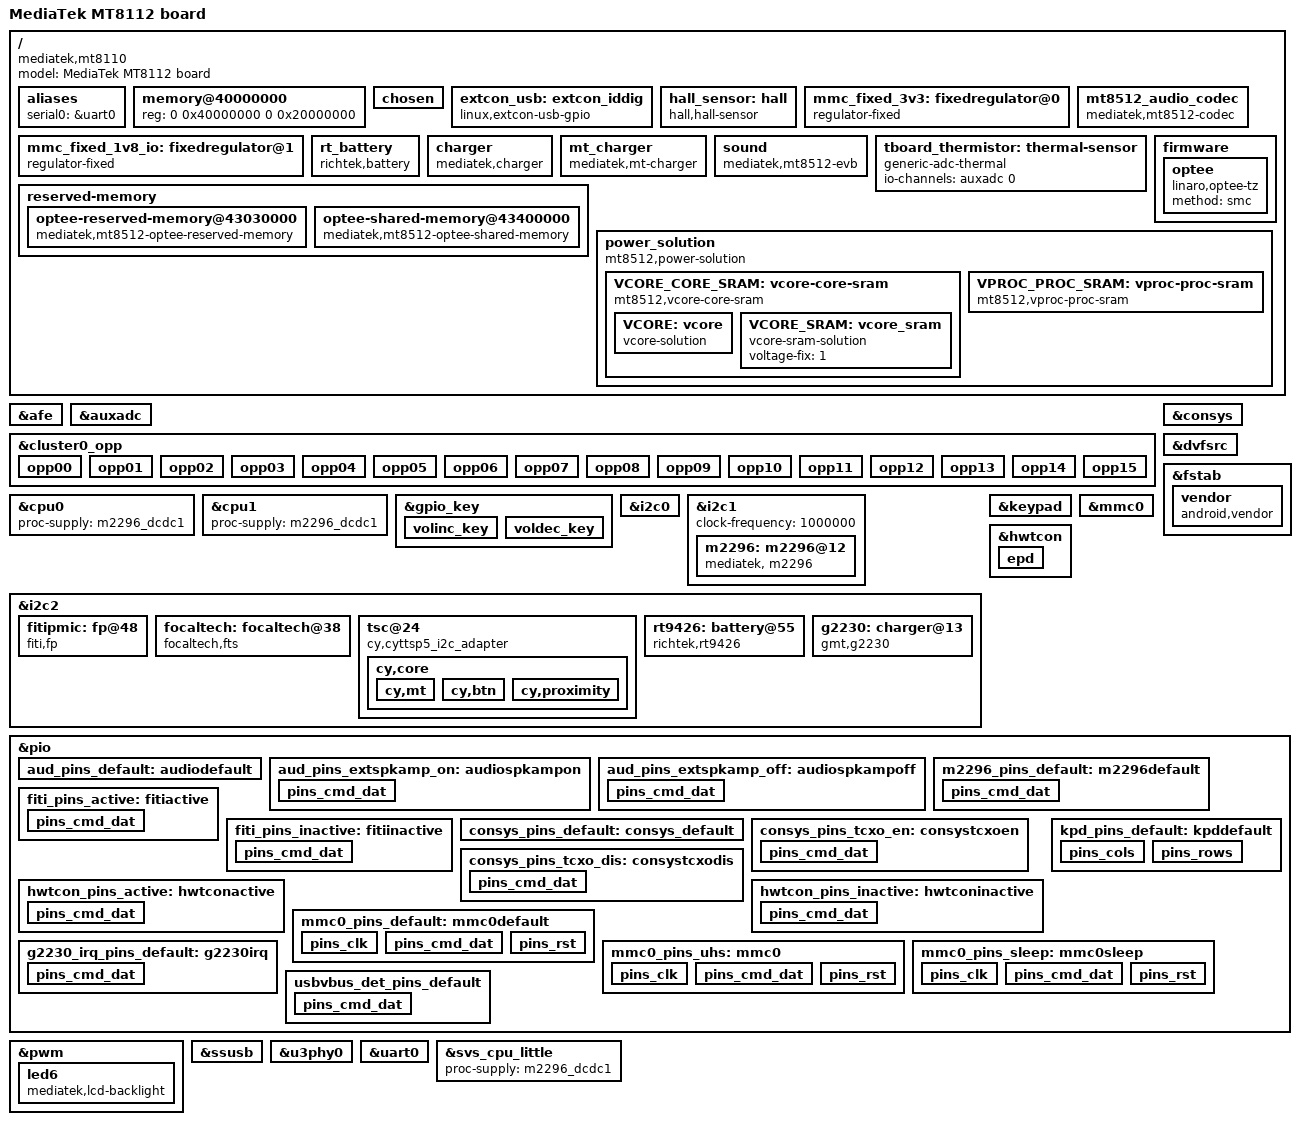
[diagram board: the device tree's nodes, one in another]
/*
 * Copyright (c) 2019 MediaTek Inc.
 *
 * SPDX-License-Identifier: (GPL-2.0 OR MIT)
 */

/dts-v1/;
#include "mt8112.dtsi"

/ {
	model = "MediaTek MT8112 board";
	compatible = "mediatek,mt8110", "mediatek,mt8512";

	aliases {
		serial0 = &uart0;
	};

	memory@40000000 {
		device_type = "memory";
		reg = <0 0x40000000 0 0x20000000>;
	};
	chosen {
		bootargs = "console=ttyS0,921600n1 \
		root=PARTUUID=936e1662-2b63-435d-859d-1b9e5a838335 \
		rootwait skip_initramfs \
		earlycon=uart8250,mmio32,0x11002000 \
		initcall_debug androidboot.hardware=mt8512 \
		firmware_class.path=/vendor/firmware";
	};
	extcon_usb: extcon_iddig {
		compatible = "linux,extcon-usb-gpio";
		vbus-gpios = <&pio 35 0>;
		pinctrl-names = "default";
		pinctrl-0 = <&usbvbus_det_pins_default>;
	};

	hall_sensor: hall {
		compatible = "hall,hall-sensor";
		interrupt-parent = <&pio>;
		interrupts = <30 IRQ_TYPE_LEVEL_LOW>;
		int-gpio = <&pio 30 0>;
		sensor-name = "hall_sensor_1";
		sensor-num = <1>;
	};

	mmc_fixed_3v3: fixedregulator@0 {
		compatible = "regulator-fixed";
		regulator-name = "mmc_power";
		regulator-min-microvolt = <3300000>;
		regulator-max-microvolt = <3300000>;
		enable-active-high;
		regulator-always-on;
	};

	mmc_fixed_1v8_io: fixedregulator@1 {
		compatible = "regulator-fixed";
		regulator-name = "mmc_io";
		regulator-min-microvolt = <1800000>;
		regulator-max-microvolt = <1800000>;
		enable-active-high;
		regulator-always-on;
	};

	mt8512_audio_codec: mt8512_audio_codec {
		compatible = "mediatek,mt8512-codec";
		mediatek,afe-regmap = <&afe>;
		mediatek,apmixedsys-regmap = <&apmixedsys>;
		mediatek,downlink-nle-support = <1>;
		clocks = <&topckgen CLK_TOP_AUD_INTBUS_SEL>;
		clock-names = "bus";
		io-channels = <&auxadc 5>;
		io-channel-names = "adc-ch5";
	};

	rt_battery: rt_battery {
		compatible = "richtek,battery";
		status = "okay";
	};

	charger: charger {
		compatible = "mediatek,charger";
		algorithm_name = "switch_charging";
		/* enable_sw_jeita; */

		/* common */
		battery_cv = <4350000>;
		max_charger_voltage = <6500000>;
		max_charging_time = <72000>; /* 20 * 60 * 60 secs */
		enable_sw_safety_timer;

		/* charging current */
		usb_charger_current_suspend = <0>;
		usb_charger_current_unconfigured = <70000>;
		usb_charger_current_configured = <400000>;
		usb_charger_current = <400000>;
		ac_charger_current = <1000000>;
		ac_charger_input_current = <3000000>;
		non_std_ac_charger_current = <2000000>;
		charging_host_charger_current = <400000>;
		apple_1_0a_charger_current = <650000>;
		apple_2_1a_charger_current = <800000>;
		ta_ac_charger_current = <1000000>;

		/* sw jeita */
		jeita_temp_above_t4_cv_voltage = <4240000>;
		jeita_temp_t3_to_t4_cv_voltage = <4240000>;
		jeita_temp_t2_to_t3_cv_voltage = <4340000>;
		jeita_temp_t1_to_t2_cv_voltage = <4240000>;
		jeita_temp_t0_to_t1_cv_voltage = <4040000>;
		jeita_temp_below_t0_cv_voltage = <4040000>;
		temp_t4_threshold = <50>;
		temp_t4_thres_minus_x_degree = <47>;
		temp_t3_threshold = <45>;
		temp_t3_thres_minus_x_degree = <39>;
		temp_t2_threshold = <10>;
		temp_t2_thres_plus_x_degree = <16>;
		temp_t1_threshold = <0>;
		temp_t1_thres_plus_x_degree = <6>;
		temp_t0_threshold = <0>;
		temp_t0_thres_plus_x_degree = <0>;
		temp_neg_10_threshold = <0>;

		/* battery temperature protection */
		enable_min_charge_temperature;
		min_charge_temperature = <0>;
		min_charge_temperature_plus_x_degree = <6>;
		max_charge_temperature = <50>;
		max_charge_temperature_minus_x_degree = <47>;
	};

	mt_charger: mt_charger {
		compatible = "mediatek,mt-charger";
		status = "okay";
	};

	reserved-memory {
		optee-reserved-memory@43030000 {
			compatible = "mediatek,mt8512-optee-reserved-memory";
			no-map;
			reg = <0 0x43030000 0 0x3d0000>;
		};
		optee-shared-memory@43400000 {
			compatible = "mediatek,mt8512-optee-shared-memory";
			no-map;
			reg = <0 0x43400000 0 0x100000>;
		};
	};

	sound: sound {
		compatible = "mediatek,mt8512-evb";
		mediatek,platform = <&afe>;
		mediatek,int-adda-audio-codec=<&mt8512_audio_codec>;
		mediatek,int-adda-codec-dai-name="mt8512-codec-dai";
		pinctrl-names = "default",
			"ext_spk_amp_on",
			"ext_spk_amp_off";
		pinctrl-0 = <&aud_pins_default>;
		pinctrl-1 = <&aud_pins_extspkamp_on>;
		pinctrl-2 = <&aud_pins_extspkamp_off>;
		status = "okay";
	};

	tboard_thermistor: thermal-sensor {
		compatible = "generic-adc-thermal";
		#thermal-sensor-cells = <0>;
		io-channels = <&auxadc 0>;
		io-channel-names = "sensor-channel";
	};

	firmware {
		optee {
			compatible = "linaro,optee-tz";
			method = "smc";
		};
	};

	power_solution: power_solution {
		compatible = "mt8512,power-solution";
		power-states = <&VCORE_CORE_SRAM &VPROC_PROC_SRAM>;
		device-names = <0>;
		clk-on = <0>;
		buck-name = "rt";

		VCORE_CORE_SRAM: vcore-core-sram {
			compatible = "mt8512,vcore-core-sram";
			merge = <0>;
			bucks = <&VCORE &VCORE_SRAM>;

			VCORE: vcore {
				compatible = "vcore-solution";
				type = "gpio";
				channel = <1>;
				latency = <100>;
				voltage-fix = <0>;
			};

			VCORE_SRAM: vcore_sram {
				compatible = "vcore-sram-solution";
				voltage-fix = <1>;
			};
		};

		VPROC_PROC_SRAM: vproc-proc-sram {
			compatible = "mt8512,vproc-proc-sram";
			merge = <1>;
			fix = <1>;
		};
	};
};

&afe {
	status = "okay";
};

&auxadc {
	status = "okay";
};

&cluster0_opp {
	opp00 {
		opp-hz = /bits/ 64 <600000000>;
		opp-microvolt = <800000>;
	};
	opp01 {
		opp-hz = /bits/ 64 <666000000>;
		opp-microvolt = <800000>;
	};
	opp02 {
		opp-hz = /bits/ 64 <733000000>;
		opp-microvolt = <800000>;
	};
	opp03 {
		opp-hz = /bits/ 64 <833000000>;
		opp-microvolt = <800000>;
	};
	opp04 {
		opp-hz = /bits/ 64 <1000000000>;
		opp-microvolt = <800000>;
	};
	opp05 {
		opp-hz = /bits/ 64 <1133000000>;
		opp-microvolt = <800000>;
	};
	opp06 {
		opp-hz = /bits/ 64 <1266000000>;
		opp-microvolt = <800000>;
	};
	opp07 {
		opp-hz = /bits/ 64 <1400000000>;
		opp-microvolt = <800000>;
	};
	opp08 {
		opp-hz = /bits/ 64 <1467000000>;
		opp-microvolt = <825000>;
	};
	opp09 {
		opp-hz = /bits/ 64 <1534000000>;
		opp-microvolt = <850000>;
	};
	opp10 {
		opp-hz = /bits/ 64 <1588000000>;
		opp-microvolt = <868750>;
	};
	opp11 {
		opp-hz = /bits/ 64 <1702000000>;
		opp-microvolt = <912500>;
	};
	opp12 {
		opp-hz = /bits/ 64 <1786000000>;
		opp-microvolt = <943750>;
	};
	opp13 {
		opp-hz = /bits/ 64 <1870000000>;
		opp-microvolt = <975000>;
	};
	opp14 {
		opp-hz = /bits/ 64 <1938000000>;
		opp-microvolt = <1000000>;
	};
	opp15 {
		opp-hz = /bits/ 64 <2000000000>;
		opp-microvolt = <1025000>;
	};
};

&cpu0 {
	proc-supply = <&m2296_dcdc1>;
};

&cpu1 {
	proc-supply = <&m2296_dcdc1>;
};

&consys {
	pinctrl-names = "default",
		"consys_pins_tcxo_en",
		"consys_pins_tcxo_dis";
	pinctrl-0 = <&consys_pins_default>;
	pinctrl-1 = <&consys_pins_tcxo_en>;
	pinctrl-2 = <&consys_pins_tcxo_dis>;
	1v8_en = <&pio 57 0>;	/* 1.8V */
	3v3_en = <&pio 56 0>;	/* 3.3V */
	status = "okay";
};

&dvfsrc {
	status = "okay";
	dvfsrc-pwr-index = <7>;
	clocks = <&infrasys CLK_INFRA_DVFSRC>,
		<&topckgen CLK_TOP_I2C_SEL>,
		<&infrasys CLK_INFRA_I2C0_AXI>;
	clock-names = "dvfsrc",
		"i2c_sel",
		"i2c0";
};

&fstab {
	vendor {
		compatible = "android,vendor";
		dev = "/dev/block/platform/11230000.mmc/by-name/vendor";
		type = "ext4";
		mnt_flags = "ro";
		fsmgr_flags = "wait";
	};
};

&gpio_key {
	volinc_key{
		debounce-interval = <100>;
		gpios = <&pio 42 1>;
		linux,code = <115>;
		linux,input-type = <1>;
	};
	voldec_key{
		debounce-interval = <100>;
		gpios = <&pio 43 1>;
		linux,code = <114>;
		linux,input-type = <1>;
	};
};

&i2c0 {
	status = "okay";
};

&i2c1 {
	clock-frequency = <1000000>;
	status = "okay";

	m2296: m2296@12 {
		compatible = "mediatek, m2296";
		reg = <0x12>;
		interrupt-parent = <&pio>;
		interrupts = <62 IRQ_TYPE_EDGE_FALLING>;
		interrupt-controller;
		#interrupt-cells = <2>;
		pinctrl-names = "default";
		pinctrl-0 = <&m2296_pins_default>;
		system-power-controller;
		mediatek,pwrkey-code = <116>;
		status = "okay";
	};
};

&i2c2 {
	status = "okay";

	fitipmic: fp@48 {
		compatible = "fiti,fp";
		reg = <0x18>;
		vgh_ext = <0>;
		vgl_ext = <2000>;
		xon_len = <2510>;
		xon_delay = <40>;
		vgh = <25000>;
		vgl = <20000>;
		vcom_setting = <2770>;
		vghnm_setting = <3300>;
		vghnm_ext = <1500>;
		vpos = <15000>;
		vneg = <15000>;
		epd-pmic-en = <&pio 38 0>;
		epd-pmic-op = <&pio 9 0>;
		epd-pmic-nm = <&pio 10 0>;
		interrupt-parent = <&pio>;
		interrupts = <10 IRQ_TYPE_LEVEL_HIGH>;
		deb-gpios = <&pio 5 0>;
		debounce = <16>;
		/*epd-supply = <&m2296_dcdc3>;*/
		pinctrl-names = "active", "inactive";
		pinctrl-0 = <&fiti_pins_active>;
		pinctrl-1 = <&fiti_pins_inactive>;
		status = "okay";
	};

	focaltech:focaltech@38 {
		compatible = "focaltech,fts";
		reg = <0x38>;
		focaltech,name = "focaltech";
		focaltech,panel-coords = <0 0 0x400 0x2f6>;
		focaltech,display-coords = <0 0 0x400 0x2f6>;
		/*focaltech,i2c-pull-up;*/
		/*focaltech,no-force-update;*/
		focaltech,reset-gpio = <&pio 0 0>;
		focaltech,irq-gpio = <&pio 1 0>;
		/*wacom,pdctb = <&pio 4 0>;*/
		/*interrupt-parent = <&sysirq>;*/
		interrupt-parent = <&pio>;
		interrupts = <0 IRQ_TYPE_EDGE_FALLING>;
		focaltech,fw-name = "FT_Upgrade_App.i";
		focaltech,group-id = <0x01>;
		focaltech,hard-reset-delay-ms = <0x14>;
		focaltech,soft-reset-delay-ms = <0x0a>;
		focaltech,num-max-touches = <0x0a>;
		focaltech,fw-delay-aa-ms = <0x32>;
		focaltech,fw-delay-55-ms = <0x1e>;
		focaltech,fw-upgrade-id1 = <0x79>;
		focaltech,fw-upgrade-id2 = <0x03>;
		focaltech,fw-delay-readid-ms = <0x0a>;
		focaltech,fw-delay-era-flsh-ms = <0x7d0>;
		/*focaltech,fw-auto-cal;*/
		/*focaltech,fw-vkey-support;*/
		/*focaltech,ignore-id-check;*/
		/*focaltech,psensor-support;*/
		focaltech,power-regulator-support;
		focaltech,family-id = <0x54>;
		/*focaltech,button-map*/
		status = "okay";
	};

	tsc@24 {
		compatible = "cy,cyttsp5_i2c_adapter";
		reg = <0x24>;

		/* GPIO 1, high-to-low edge triggered */
		interrupts = <1 2>;
		interrupt-parent = <&pio>;
		cy,adapter_id = "cyttsp5_i2c_adapter";

		cy,core {
			cy,name = "cyttsp5_core";

			cy,irq_gpio = <&pio 1 0>;
			cy,rst_gpio = <&pio 0 0>;
			cy,hid_desc_register = <1>;
			/*CY_CORE_FLAG_RESTORE_PARAMETERS */
			cy,flags = <4>;
			/* CY_CORE_EWG_NONE */
			cy,easy_wakeup_gesture = <0>;
			cy,btn_keys = <172 /* KEY_HOMEPAGE */
	/* previously was KEY_HOME, new Android versions use KEY_HOMEPAGE */
				       139 /* KEY_MENU */
				       158 /* KEY_BACK */
				       217 /* KEY_SEARCH */
				       114 /* KEY_VOLUMEDOWN */
				       115 /* KEY_VOLUMEUP */
				       212 /* KEY_CAMERA */
				       116>; /* KEY_POWER */
			cy,btn_keys-tag = <0>;

			cy,mt {
				cy,name = "cyttsp5_mt";

				cy,inp_dev_name = "cyttsp5_mt";
	/* CY_MT_FLAG_FLIP | CY_MT_FLAG_INV_X | CY_MT_FLAG_INV_Y */
				cy,flags = <0x18>;
				cy,abs =
	/* ABS_MT_POSITION_X, CY_ABS_MIN_X, CY_ABS_MAX_X, 0, 0 */
					<0x35 0 880 0 0
	/* ABS_MT_POSITION_Y, CY_ABS_MIN_Y, CY_ABS_MAX_Y, 0, 0 */
					0x36 0 1280 0 0
	/* ABS_MT_PRESSURE, CY_ABS_MIN_P, CY_ABS_MAX_P, 0, 0 */
					0x3a 0 255 0 0
	/* CY_IGNORE_VALUE, CY_ABS_MIN_W, CY_ABS_MAX_W, 0, 0 */
					0xffff 0 255 0 0
	/* ABS_MT_TRACKING_ID, CY_ABS_MIN_T, CY_ABS_MAX_T, 0, 0 */
					0x39 0 15 0 0
	/* ABS_MT_TOUCH_MAJOR, 0, 255, 0, 0 */
					0x30 0 255 0 0
	/* ABS_MT_TOUCH_MINOR, 0, 255, 0, 0 */
					0x31 0 255 0 0
	/* ABS_MT_ORIENTATION, -127, 127, 0, 0 */
					0x34 0xffffff81 127 0 0
	/* ABS_MT_TOOL_TYPE, 0, MT_TOOL_MAX, 0, 0 */
					0x37 0 1 0 0
	/* ABS_MT_DISTANCE, 0, 255, 0, 0 */
					0x3b 0 255 0 0>;

				cy,vkeys_x = <720>;
				cy,vkeys_y = <1280>;

				cy,virtual_keys =
				/* KeyCode CenterX CenterY Width Height */
					/* KEY_BACK */
					<158 1360 90 160 180
					/* KEY_MENU */
					139 1360 270 160 180
					/* KEY_HOMEPAGE */
					172 1360 450 160 180
					/* KEY SEARCH */
					217 1360 630 160 180>;
			};

			cy,btn {
				cy,name = "cyttsp5_btn";

				cy,inp_dev_name = "cyttsp5_btn";
			};

			cy,proximity {
				cy,name = "cyttsp5_proximity";

				cy,inp_dev_name = "cyttsp5_proximity";
				cy,abs =
					<0x19 0 1 0 0>;
			};
		};
	};

	rt9426: battery@55 {
		compatible = "richtek,rt9426";
		reg = <0x55>;
		interrupt-parent = <&pio>;
		interrupts = <28 0>;
		status = "okay";
	};

	g2230:charger@13 {
		compatible = "gmt,g2230";
		charger_name = "primary_chg";
		pinctrl-names = "default";
		pinctrl-0 = <&g2230_irq_pins_default>;
		reg = <0x13>;
		chg_ce = <&pio 31 0>;
		chg_int = <&pio 29 0>;
		status = "okay";
	};
};

&keypad {
	pinctrl-names = "default";
	pinctrl-0 = <&kpd_pins_default>;
	status = "okay";
	mediatek,kpd-key-debounce = <1024>;
	mediatek,kpd-sw-pwrkey = <116>;
	mediatek,kpd-hw-pwrkey = <1>;
	mediatek,kpd-sw-rstkey  = <114>;
	mediatek,kpd-hw-rstkey = <3>;
	mediatek,kpd-use-extend-type = <0>;
	/*HW Keycode [0~3] -> Linux Keycode*/
	mediatek,kpd-hw-map-num = <72>;
	mediatek,kpd-hw-init-map =
			<115 0 0 0 0 0 0 0 0 0 0 0 0
			 0 0 0 0 0 0 0 0 0 0 0 0 0 0 0 0 0 0 0 0 0 0 0 0
			 0 0 0 0 0 0 0 0 0 0 0 0 0 0 0 0 0 0 0 0 0 0 0 0
			 0 0 0 0 0 0 0 0 0 0 0 >;
	mediatek,kpd-pwrkey-eint-gpio = <0>;
	mediatek,kpd-pwkey-gpio-din  = <0>;
	mediatek,kpd-hw-dl-key0 = <0>;
	mediatek,kpd-hw-dl-key1 = <3>;
	mediatek,kpd-hw-dl-key2 = <1>;
	mediatek,kpd-hw-recovery-key = <0>;
	mediatek,kpd-hw-factory-key  = <3>;
};

&mmc0 {
	status = "okay";
	pinctrl-names = "default", "state_uhs", "sleep";
	pinctrl-0 = <&mmc0_pins_default>;
	pinctrl-1 = <&mmc0_pins_uhs>;
	pinctrl-2 = <&mmc0_pins_sleep>;
	bus-width = <8>;
	max-frequency = <200000000>;
	cap-mmc-highspeed;
	mmc-hs200-1_8v;
	cap-cqe;
	cap-cqe_dcmd;
	vmmc-supply = <&mmc_fixed_3v3>;
	vqmmc-supply = <&mmc_fixed_1v8_io>;
	assigned-clocks = <&topckgen CLK_TOP_MSDC50_0_SEL>;
	assigned-clock-parents = <&topckgen CLK_TOP_MSDCPLL_D2>;
	non-removable;
	no-sd;
	no-sdio;
};

&hwtcon {
	status = "okay";
	pinctrl-names = "active","inactive";
	pinctrl-0 = <&hwtcon_pins_active>;
	pinctrl-1 = <&hwtcon_pins_inactive>;
	epd{
		panel_dpi_clk = <40000000>;
		panel_width = <1024>;
		panel_height = <758>;
		panel_waveform_type = <4>;
		panel_output_8bit = <1>;
		panel_tcon0 = <6 764 31 41 0 1 0 0>;
		panel_tcon1 = <6 764 7 19 0 0 0 0>;
		panel_tcon2 = <5 766 7 7 4 0 1 7>;
		panel_tcon3 = <1 768 27 551 0 0 0 0>;
		panel_tcon4 = <1 2 7 7 4 1 1 7>;
		panel_tcon5 = <2 3 256 384 4 1 1 7>;
		panel_dpi = <6 38 6 2 5 4 1>;
		modify_wf_mode_counter = <63>;
		status = "okay";
	};
};

&pio {
	pinctrl-names = "default";

	aud_pins_default: audiodefault {
	};

	aud_pins_extspkamp_on: audiospkampon {
		pins_cmd_dat {
			pinmux = <MT8512_PIN_37_WAN_VBUS_EN__FUNC_GPIO37>;
			output-high;
		};
	};

	aud_pins_extspkamp_off: audiospkampoff {
		pins_cmd_dat {
			pinmux = <MT8512_PIN_37_WAN_VBUS_EN__FUNC_GPIO37>;
			output-low;
		};
	};

	m2296_pins_default: m2296default {
		pins_cmd_dat {
			pinmux = <MT8512_PIN_59_PMIC_DVS_REQ0__FUNC_GPIO59>,
				 <MT8512_PIN_60_PMIC_DVS_REQ1__FUNC_GPIO60>;
			output-high;
		};
	};

	fiti_pins_active: fitiactive {
		pins_cmd_dat {
			pinmux = <MT8512_PIN_10_GPIO10__FUNC_GPIO10>;
			input-enable;
		};
	};

	fiti_pins_inactive: fitiinactive {
		pins_cmd_dat {
			pinmux = <MT8512_PIN_10_GPIO10__FUNC_GPIO10>;
			input-disable;
		};
	};

	consys_pins_default: consys_default {
	};

	consys_pins_tcxo_en: consystcxoen {
		pins_cmd_dat {
			pinmux = <MT8512_PIN_54_URXD1__FUNC_CONN_TCXO_REQ>;
		};
	};

	consys_pins_tcxo_dis: consystcxodis {
		pins_cmd_dat {
			pinmux = <MT8512_PIN_54_URXD1__FUNC_GPIO54>;
			bias-disable;
		};
	};

	hwtcon_pins_active: hwtconactive {
		pins_cmd_dat {
			pinmux = <MT8512_PIN_4_GPIO4__FUNC_EPDC_D0>,
				 <MT8512_PIN_109_I2SO_DAT1__FUNC_EPDC_D1>,
				 <MT8512_PIN_5_GPIO5__FUNC_EPDC_D2>,
				 <MT8512_PIN_108_I2SO_DAT0__FUNC_EPDC_D3>,
				 <MT8512_PIN_6_GPIO6__FUNC_EPDC_D4>,
				 <MT8512_PIN_105_I2SO_BCK__FUNC_EPDC_D5>,
				 <MT8512_PIN_98_I2SIN_DAT3__FUNC_EPDC_D6>,
				 <MT8512_PIN_106_I2SO_LRCK__FUNC_EPDC_D7>,
				 <MT8512_PIN_97_I2SIN_DAT2__FUNC_EPDC_D8>,
				 <MT8512_PIN_87_SPDIF__FUNC_EPDC_D9>,
				 <MT8512_PIN_96_I2SIN_DAT1__FUNC_EPDC_D10>,
				 <MT8512_PIN_2_GPIO2__FUNC_EPDC_D11>,
				 <MT8512_PIN_95_I2SIN_DAT0__FUNC_EPDC_D12>,
				 <MT8512_PIN_3_GPIO3__FUNC_EPDC_D13>,
				 <MT8512_PIN_101_DMIC0_DAT1__FUNC_EPDC_D14>,
				 <MT8512_PIN_92_I2SIN_MCLK__FUNC_EPDC_D15>,
				 <MT8512_PIN_7_GPIO7__FUNC_EPDC_SDOE>,
				 <MT8512_PIN_94_I2SIN_BCK__FUNC_EPDC_GDSP>,
				 <MT8512_PIN_99_DMIC0_CLK__FUNC_EPDC_GDCLK>,
				 <MT8512_PIN_107_I2SO_MCLK__FUNC_EPDC_SDCLK>,
				 <MT8512_PIN_110_I2SO_DAT2__FUNC_EPDC_SDCE0>,
				 <MT8512_PIN_111_I2SO_DAT3__FUNC_EPDC_SDLE>,
				 <MT8512_PIN_93_I2SIN_LRCK__FUNC_EPDC_GDOE>;
				output-low;
		};
	};

	hwtcon_pins_inactive: hwtconinactive {

		pins_cmd_dat {
			pinmux = <MT8512_PIN_93_I2SIN_LRCK__FUNC_GPIO93>,
				 <MT8512_PIN_4_GPIO4__FUNC_GPIO4>,
				 <MT8512_PIN_109_I2SO_DAT1__FUNC_GPIO109>,
				 <MT8512_PIN_5_GPIO5__FUNC_GPIO5>,
				 <MT8512_PIN_108_I2SO_DAT0__FUNC_GPIO108>,
				 <MT8512_PIN_6_GPIO6__FUNC_GPIO6>,
				 <MT8512_PIN_105_I2SO_BCK__FUNC_GPIO105>,
				 <MT8512_PIN_98_I2SIN_DAT3__FUNC_GPIO98>,
				 <MT8512_PIN_106_I2SO_LRCK__FUNC_GPIO106>,
				 <MT8512_PIN_97_I2SIN_DAT2__FUNC_GPIO97>,
				 <MT8512_PIN_87_SPDIF__FUNC_GPIO87>,
				 <MT8512_PIN_96_I2SIN_DAT1__FUNC_GPIO96>,
				 <MT8512_PIN_2_GPIO2__FUNC_GPIO2>,
				 <MT8512_PIN_95_I2SIN_DAT0__FUNC_GPIO95>,
				 <MT8512_PIN_3_GPIO3__FUNC_GPIO3>,
				 <MT8512_PIN_101_DMIC0_DAT1__FUNC_GPIO101>,
				 <MT8512_PIN_92_I2SIN_MCLK__FUNC_GPIO92>,
				 <MT8512_PIN_7_GPIO7__FUNC_GPIO7>,
				 <MT8512_PIN_94_I2SIN_BCK__FUNC_GPIO94>,
				 <MT8512_PIN_99_DMIC0_CLK__FUNC_GPIO99>,
				 <MT8512_PIN_107_I2SO_MCLK__FUNC_GPIO107>,
				 <MT8512_PIN_110_I2SO_DAT2__FUNC_GPIO110>,
				 <MT8512_PIN_111_I2SO_DAT3__FUNC_GPIO111>;
				input-enable;
		};
	};

	kpd_pins_default: kpddefault {
		pins_cols {
			pinmux = <MT8512_PIN_42_KPCOL0__FUNC_KPCOL0>,
				 <MT8512_PIN_43_KPCOL1__FUNC_KPCOL1>;
			input-enable;
			bias-pull-up = <MTK_PUPD_SET_R1R0_01>;
		};

		pins_rows {
			pinmux = <MT8512_PIN_41_KPROW1__FUNC_KPROW1>,
				 <MT8512_PIN_41_KPROW1__FUNC_KPROW1>;
			output-low;
			bias-disable;
		};
	};

	mmc0_pins_default: mmc0default {
		pins_clk {
			pinmux = <MT8512_PIN_82_MSDC0_CLK__FUNC_MSDC0_CLK>;
			bias-pull-down;
		};

		pins_cmd_dat {
			pinmux = <MT8512_PIN_86_MSDC0_DAT0__FUNC_MSDC0_DAT0>,
				 <MT8512_PIN_85_MSDC0_DAT1__FUNC_MSDC0_DAT1>,
				 <MT8512_PIN_84_MSDC0_DAT2__FUNC_MSDC0_DAT2>,
				 <MT8512_PIN_83_MSDC0_DAT3__FUNC_MSDC0_DAT3>,
				 <MT8512_PIN_79_MSDC0_DAT4__FUNC_MSDC0_DAT4>,
				 <MT8512_PIN_78_MSDC0_DAT5__FUNC_MSDC0_DAT5>,
				 <MT8512_PIN_77_MSDC0_DAT6__FUNC_MSDC0_DAT6>,
				 <MT8512_PIN_76_MSDC0_DAT7__FUNC_MSDC0_DAT7>,
				 <MT8512_PIN_81_MSDC0_CMD__FUNC_MSDC0_CMD>;
			input-enable;
			bias-pull-up;
		};

		pins_rst {
			pinmux = <MT8512_PIN_80_MSDC0_RSTB__FUNC_MSDC0_RSTB>;
			bias-pull-up;
		};
	};

	mmc0_pins_uhs: mmc0 {
		pins_clk {
			pinmux = <MT8512_PIN_82_MSDC0_CLK__FUNC_MSDC0_CLK>;
			drive-strength = <MTK_DRIVE_6mA>;
			bias-pull-down = <MTK_PUPD_SET_R1R0_01>;
		};

		pins_cmd_dat {
			pinmux = <MT8512_PIN_86_MSDC0_DAT0__FUNC_MSDC0_DAT0>,
				 <MT8512_PIN_85_MSDC0_DAT1__FUNC_MSDC0_DAT1>,
				 <MT8512_PIN_84_MSDC0_DAT2__FUNC_MSDC0_DAT2>,
				 <MT8512_PIN_83_MSDC0_DAT3__FUNC_MSDC0_DAT3>,
				 <MT8512_PIN_79_MSDC0_DAT4__FUNC_MSDC0_DAT4>,
				 <MT8512_PIN_78_MSDC0_DAT5__FUNC_MSDC0_DAT5>,
				 <MT8512_PIN_77_MSDC0_DAT6__FUNC_MSDC0_DAT6>,
				 <MT8512_PIN_76_MSDC0_DAT7__FUNC_MSDC0_DAT7>,
				 <MT8512_PIN_81_MSDC0_CMD__FUNC_MSDC0_CMD>;
			input-enable;
			drive-strength = <MTK_DRIVE_6mA>;
			bias-pull-up = <MTK_PUPD_SET_R1R0_01>;
		};

		pins_rst {
			pinmux = <MT8512_PIN_80_MSDC0_RSTB__FUNC_MSDC0_RSTB>;
			bias-pull-up;
		};
	};

	mmc0_pins_sleep: mmc0sleep {
		pins_clk {
			pinmux = <MT8512_PIN_82_MSDC0_CLK__FUNC_GPIO82>;
			bias-disable;
			input-disable;
		};

		pins_cmd_dat {
			pinmux = <MT8512_PIN_86_MSDC0_DAT0__FUNC_GPIO86>,
				 <MT8512_PIN_85_MSDC0_DAT1__FUNC_GPIO85>,
				 <MT8512_PIN_84_MSDC0_DAT2__FUNC_GPIO84>,
				 <MT8512_PIN_83_MSDC0_DAT3__FUNC_GPIO83>,
				 <MT8512_PIN_79_MSDC0_DAT4__FUNC_GPIO79>,
				 <MT8512_PIN_78_MSDC0_DAT5__FUNC_GPIO78>,
				 <MT8512_PIN_77_MSDC0_DAT6__FUNC_GPIO77>,
				 <MT8512_PIN_76_MSDC0_DAT7__FUNC_GPIO76>,
				 <MT8512_PIN_81_MSDC0_CMD__FUNC_GPIO81>;
			bias-disable;
			input-disable;
		};

		pins_rst {
			pinmux = <MT8512_PIN_80_MSDC0_RSTB__FUNC_GPIO80>;
			bias-disable;
			input-disable;
		};
	};

	g2230_irq_pins_default: g2230irq {
		pins_cmd_dat {
			pinmux = <MT8512_PIN_29_CHG_IRQ__FUNC_GPIO29>;
			input-enable;
			bias-pull-up;
		};
	};

	usbvbus_det_pins_default: usbvbus_det_pins_default {
		pins_cmd_dat {
			pinmux = <MT8512_PIN_35_WAN_FM_RDY__FUNC_GPIO35>;
			input-enable;
			bias-disable;
		};
	};
};

&pwm {
	status = "okay";
	led6 {
		compatible = "mediatek,lcd-backlight";
		led_mode = <1>;
		data = <0>;
		pwm_config = <0 0 0 0 0>;
	};
};

&ssusb {
	extcon = <&extcon_usb>;
	dr_mode = "otg";
	phys = <&u2port0 PHY_TYPE_USB2>;
	mediatek,force_vbus = "true";
	status="okay";
};

&u3phy0 {
	status = "okay";
};

&uart0 {
	status = "okay";
};

&svs_cpu_little {
	proc-supply = <&m2296_dcdc1>;
};

#include "m2296.dtsi"
#include "rt9426.dtsi"
